# AT32UC3B1256 device description
Architecture: AVR32_UC3; Family: AVR UC3
Registers are 32-bit, read-write, reset 0x0 unless marked. A register's access mark holds for its fields unless they carry their own. Offsets are from the block's base; [hi:lo] are bit positions; {n}, {i} and the like mark numbered series; 'fields as' and 'values as' point back to an identical list.

## TWI — Two-wire Interface
Instances: TWI 0xffff2c00
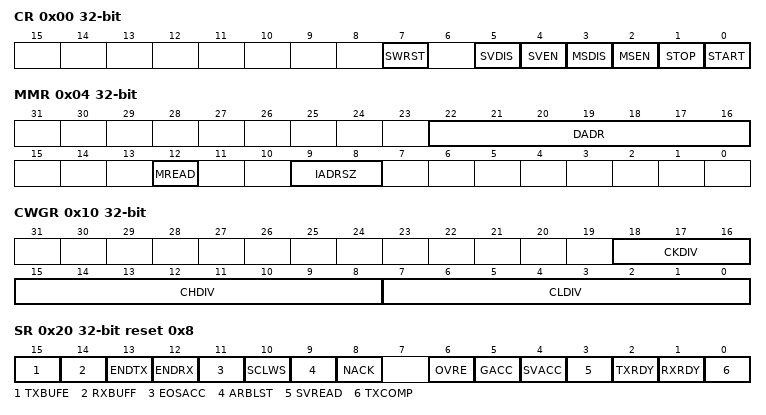
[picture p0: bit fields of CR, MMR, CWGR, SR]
0x00 CR wo reset not defined — Control Register
  [7] SWRST — Software Reset
  [5] SVDIS — TWI Slave Transfer Disable
  [4] SVEN — TWI Slave Transfer Enable
  [3] MSDIS — TWI Master Transfer Disable
  [2] MSEN — TWI Master Transfer Enable
  [1] STOP — Send a STOP Condition
  [0] START — Send a START Condition
0x04 MMR — Master Mode Register
  [22:16] DADR — Device Address
  [12] MREAD — Master Read Direction
  [9:8] IADRSZ — Internal Device Address Size
    0=NO_ADDR; 1=ONE_BYTE; 2=TWO_BYTES; 3=THREE_BYTES
0x08 SMR — Slave Mode Register
  [22:16] SADR — Slave Device Address
0x0C IADR — Internal Address Register
  [23:0] IADR — Internal Address
0x10 CWGR — Clock Waveform Generator Register
  [18:16] CKDIV — Clock Divider
  [15:8] CHDIV — Clock High Divider
  [7:0] CLDIV — Clock Low Divider
0x20 SR ro reset 0x8 — Status Register
  [15] TXBUFE — TX Buffer Empty
  [14] RXBUFF — RX Buffer Full
  [13] ENDTX — End of TX Buffer
  [12] ENDRX — End of RX Buffer
  [11] EOSACC — End Of Slave Access
  [10] SCLWS — Clock Wait State
  [9] ARBLST — Arbitration Lost
  [8] NACK — Not Acknowledged
  [6] OVRE — Overrun Error
  [5] GACC — General Call Access
  [4] SVACC — Slave Access
  [3] SVREAD — Slave Read
  [2] TXRDY — Transmit holding register Ready
  [1] RXRDY — Receive holding register Ready
  [0] TXCOMP — Transmission Completed
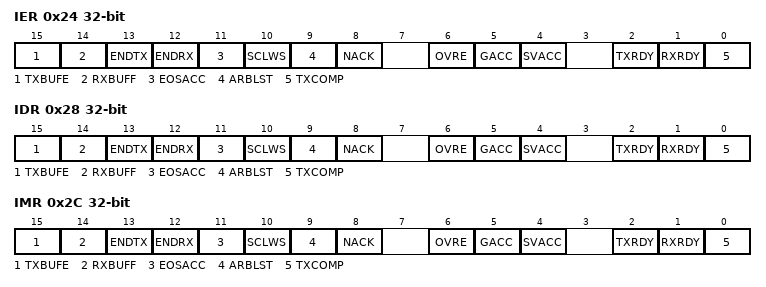
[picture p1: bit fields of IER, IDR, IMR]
0x24 IER wo reset not defined — Interrupt Enable Register
  [15] TXBUFE — TX Buffer Empty
  [14] RXBUFF — RX Buffer Full
  [13] ENDTX — End of TX Buffer
  [12] ENDRX — End of RX Buffer
  [11] EOSACC — End of Slave Access
  [10] SCLWS — Clock Wait State
  [9] ARBLST — Arbitration Lost
  [8] NACK — Not Acknowledge
  [6] OVRE — Overrun Error
  [5] GACC — General Call Access
  [4] SVACC — Slave Access
  [2] TXRDY — Transmit holding register Ready
  [1] RXRDY — Receive holding register Ready
  [0] TXCOMP — Transmission Completed
0x28 IDR wo reset not defined — Interrupt Disable Register
  fields as IER
0x2C IMR ro — Interrupt Mask Register
  [15] TXBUFE — TX Buffer Empty
  [14] RXBUFF — RX Buffer Full
  [13] ENDTX — End of RX Buffer
  [12] ENDRX — End of RX Buffer
  [11] EOSACC — End of Slave Access
  [10] SCLWS — Clock Wait State
  [9] ARBLST — Arbitration Lost
  [8] NACK — Not Acknowledge
  [6] OVRE — Overrun Error
  [5] GACC — General Call Access
  [4] SVACC — Slave Access
  [2] TXRDY — Transmit holding register Ready
  [1] RXRDY — Receive holding register Ready
  [0] TXCOMP — Transmission Completed
0x30 RHR ro — Receive Holding Register
  [7:0] RXDATA — Master or Slave Receive Data
0x34 THR wo reset not defined — Transmit Holding Register
  [7:0] TXDATA — Master or Slave Transmit Holding Data

## WDT — Watchdog Timer
Instances: WDT 0xffff0d30
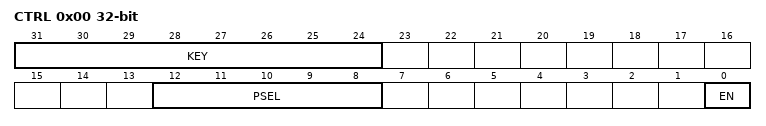
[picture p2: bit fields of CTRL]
0x00 CTRL — WDT Control
  [31:24] KEY
  [12:8] PSEL — Prescale Select
  [0] EN — WDT Enable
0x04 CLR wo — WDT Clear

## FLASH_FUSES — Fuses
Instances: FUSES 0xFFFE1400 in fuses
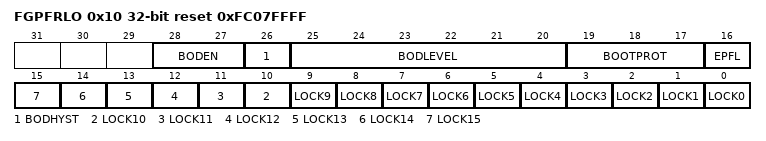
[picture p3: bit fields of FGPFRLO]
0x10 FGPFRLO reset 0xFC07FFFF — Flash Controller General Purpose Fuse Register Low
  [28:27] BODEN — Brownout detector enable
    0=BOD_DISABLED; 1=BOD_ENABLED_RESET_ENABLED (BOD enabled, BOD reset enabled); 2=BOD_ENABLED_RESET_DISABLED (BOD enabled, BOD reset disabled); 3=BOD_DISABLED2
  [26] BODHYST — Brownout detector hysteresis
    0=BODHYST_DISABLED (Disabled); 1=BODHYST_ENABLED (Enabled)
  [25:20] BODLEVEL — Brownout detector trigger level
    0=BOD_LEVEL_OFF (BOD Level OFF (1.44V)); 23=BOD_LEVEL_1V52 (BOD Level 1.52V); 31=BOD_LEVEL_1V56 (BOD Level 1.61V); 39=BOD_LEVEL_1V71 (BOD Level 1.71V)
  [19:17] BOOTPROT — Bootloader protection
    0=BOOTAREA_64KB (Boot area: 64 Kbyte); 1=BOOTAREA_32KB (Boot area: 32 Kbyte); 2=BOOTAREA_16KB (Boot area: 16 Kbyte); 3=BOOTAREA_8KB (Boot area: 8 Kbyte); 4=BOOTAREA_4KB (Boot area: 4 Kbyte); 5=BOOTAREA_2KB (Boot area: 2 Kbyte); 6=BOOTAREA_1KB (Boot area: 1 Kbyte); 7=BOOTAREA_0B (Boot area: 0 byte)
  [16] EPFL — External privileged fetch lock
    0=EPFL_LOCK (External privileged fetch locked); 1=EPFL_NO_LOCK (External privileged fetch not locked)
  [n] LOCK{n} (n=0..15)
